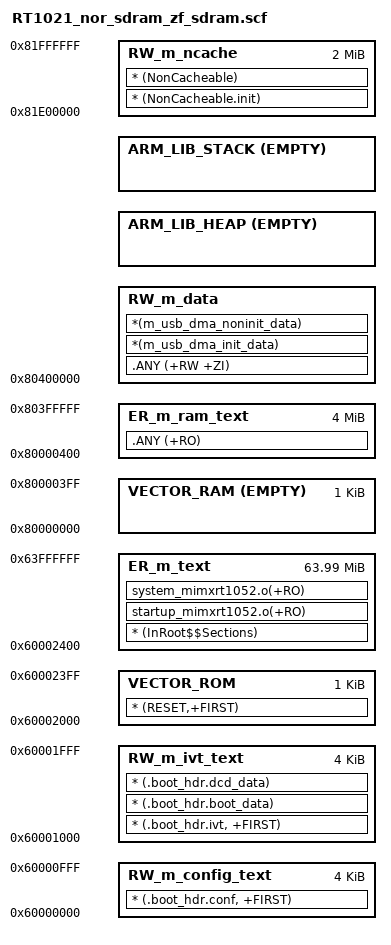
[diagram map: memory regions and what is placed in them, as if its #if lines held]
#! armcc -E
/*
** ###################################################################
**     Processors:          MIMXRT1021CAF4A
**                          MIMXRT1021CAG4A
**                          MIMXRT1021DAF5A
**                          MIMXRT1021DAG5A
**
**     Compiler:            Keil ARM C/C++ Compiler
**     Reference manual:    IMXRT1020RM Rev. 1RC, 05/2018
**     Version:             rev. 0.1, 2017-06-06
**     Build:               b180801
**
**     Abstract:
**         Linker file for the Keil ARM C/C++ Compiler
**
**     Copyright 2016 Freescale Semiconductor, Inc.
**     Copyright 2016-2018 NXP
**
**     SPDX-License-Identifier: BSD-3-Clause
**
**     http:                 www.nxp.com
**     mail:                 support@nxp.com
**
** ###################################################################
*/

#define m_flash_config_start           0x60000000
#define m_flash_config_size            0x00001000

#define m_ivt_start                    0x60001000
#define m_ivt_size                     0x00001000

#define m_interrupts_start             0x60002000
#define m_interrupts_size              0x00000400

#define m_text_start                   0x60002400
#define m_text_size                    0x03FFDC00

;在SDRAM中存放代码的空间
;中断向量表
#define m_sdram_interrupts_start       0x80000000
#define m_sdram_interrupts_size        0x00000400

;SDRAM中的主体代码
#define m_sdram_text_start             0x80000400
#define m_sdram_text_size              0x003FFC00

#define m_data_start                   0x80400000
#define m_data_size                    0x01A00000

#define m_ncache_start                 0x81E00000
#define m_ncache_size                  0x00200000

#define m_data2_start                  0x20000000
#define m_data2_size                   0x00010000

#define m_data3_start                  0x20200000
#define m_data3_size                   0x00020000

/* Sizes */
#if (defined(__stack_size__))
  #define Stack_Size                   __stack_size__
#else
  #define Stack_Size                   0x0400
#endif

#if (defined(__heap_size__))
  #define Heap_Size                    __heap_size__
#else
  #define Heap_Size                    0x0400
#endif

LR_m_rom_config m_flash_config_start m_flash_config_size {   ; load region size_region
	RW_m_config_text m_flash_config_start m_flash_config_size { ; load address = execution address
	* (.boot_hdr.conf, +FIRST)
	}
}

LR_m_rom_ivt m_ivt_start m_ivt_size {   ; load region size_region
	RW_m_ivt_text m_ivt_start m_ivt_size { ; load address = execution address
	* (.boot_hdr.ivt, +FIRST)
	* (.boot_hdr.boot_data)
	* (.boot_hdr.dcd_data)
	}
}

LR_m_text m_interrupts_start m_text_start+m_text_size-m_interrupts_size {   ; load region size_region
  
  ; 在FALSH中的中断向量表
  VECTOR_ROM m_interrupts_start m_interrupts_size { ; load address = execution address
    * (RESET,+FIRST)
  }
  
  ; * (InRoot$$Sections)是__main中从加载域复制代码到执行域的程序scatter_copy，
  ; 启动时运行的startup_mimxrt1052t和system_mimxrt1052中的代码要存放在FLASH中
  ER_m_text m_text_start m_text_size { ; load address = execution address
    * (InRoot$$Sections)
	startup_mimxrt1052.o(+RO)
	system_mimxrt1052.o(+RO)
  } 

  ;	EMPTY表示这段空间留空，防止其它应用占用或编译提示warning
  VECTOR_RAM m_sdram_interrupts_start EMPTY m_sdram_interrupts_size { ;execution address
   
   ;这部分内容由board.c文件中的CopyAndUseRAMVectorTable函数从VECTOR_ROM中复制得到
   ;得到SDRAM版本的中断向量表
  }
  
  ;存放主体程序的SDRAM空间，由__main函数从FLASH中加载
  ER_m_ram_text m_sdram_text_start m_sdram_text_size { ;execution address
    .ANY (+RO)
  }  
  
  RW_m_data m_data_start m_data_size-Stack_Size-Heap_Size { ; RW data
    .ANY (+RW +ZI)
    *(m_usb_dma_init_data)
    *(m_usb_dma_noninit_data)
  }
  ARM_LIB_HEAP +0 EMPTY Heap_Size {    ; Heap region growing up
  }
  ARM_LIB_STACK m_data_start+m_data_size EMPTY -Stack_Size { ; Stack region growing down
  }
  RW_m_ncache m_ncache_start m_ncache_size { ; ncache RW data
    * (NonCacheable.init)
    * (NonCacheable)
  }
}
